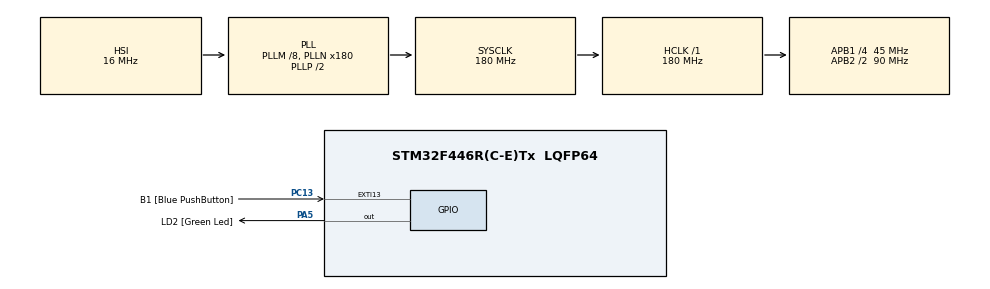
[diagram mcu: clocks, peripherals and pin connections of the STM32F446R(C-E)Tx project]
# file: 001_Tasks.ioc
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Mcu.Family=STM32F4
Mcu.Name=STM32F446R(C-E)Tx
Mcu.Package=LQFP64
NVIC.PriorityGroup=NVIC_PRIORITYGROUP_4
NVIC.TIM6_DAC_IRQn=true\:0\:0\:false\:false\:true\:false\:true\:true
NVIC.TimeBase=TIM6_DAC_IRQn
NVIC.TimeBaseIP=TIM6
PA13.GPIO_Label=TMS
PA13.Signal=SYS_JTMS-SWDIO
PA14.GPIO_Label=TCK
PA14.Signal=SYS_JTCK-SWCLK
PA2.GPIO_Label=USART_TX
PA2.Signal=USART2_TX
PA3.GPIO_Label=USART_RX
PA3.Signal=USART2_RX
PA5.GPIO_Label=LD2 [Green Led]
PA5.Signal=GPIO_Output
PB3.GPIO_Label=SWO
PB3.Signal=SYS_JTDO-SWO
PC13.GPIO_Label=B1 [Blue PushButton]
PC13.GPIO_ModeDefaultEXTI=GPIO_MODE_IT_FALLING
PC13.Signal=GPXTI13
PC14-OSC32_IN.Signal=RCC_OSC32_IN
PC15-OSC32_OUT.Signal=RCC_OSC32_OUT
PH0-OSC_IN.Signal=RCC_OSC_IN
PH1-OSC_OUT.Signal=RCC_OSC_OUT
ProjectManager.HeapSize=0x200
ProjectManager.StackSize=0x400
ProjectManager.TargetToolchain=STM32CubeIDE
RCC.AHBFreq_Value=180000000
RCC.APB1CLKDivider=RCC_HCLK_DIV4
RCC.APB1Freq_Value=45000000
RCC.APB1TimFreq_Value=90000000
RCC.APB2CLKDivider=RCC_HCLK_DIV2
RCC.APB2Freq_Value=90000000
RCC.APB2TimFreq_Value=180000000
RCC.CortexFreq_Value=180000000
RCC.FLatency-AdvancedSettings=FLASH_LATENCY_5
RCC.HCLKFreq_Value=180000000
RCC.HSE_VALUE=8000000
RCC.HSI_VALUE=16000000
RCC.LSE_VALUE=32768
RCC.PLLM=8
RCC.PLLN=180
RCC.SYSCLKFreq_VALUE=180000000
RCC.SYSCLKSource=RCC_SYSCLKSOURCE_PLLCLK
RCC.USBFreq_Value=180000000
RCC.VCOOutputFreq_Value=360000000
VP_SYS_VS_tim6.Mode=TIM6
board=NUCLEO-F446RE

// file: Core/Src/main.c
/* USER CODE BEGIN Header */
/**
  ******************************************************************************
  * @file           : main.c
  * @Author			: Abdio Tujuba
  * @brief			: Multiple task creation based on FreeRTOS
  * @IDE			; STM32CubeIDE
  * @board			: STM32F446RE NucleoBoard
  ******************************************************************************
  * @attention
  *
  * Copyright (c) 2022 STMicroelectronics.
  * All rights reserved.
  *
  * This software is licensed under terms that can be found in the LICENSE file
  * in the root directory of this software component.
  * If no LICENSE file comes with this software, it is provided AS-IS.
  *
  ******************************************************************************
  */
/* USER CODE END Header */
#include "main.h"

/* USER CODE BEGIN Includes */

#include "FreeRTOS.h"
#include "task.h"
#include <stdio.h>

/* USER CODE END Includes */

/* USER CODE BEGIN PTD */

//static UART_InitTypeDef s_USART2_Handle ;
//static UART_HandleTypeDef s_USART2_Handle;

/* USER CODE END PTD */

/* USER CODE BEGIN PV */

#define DWT_CTRL 								(*(volatile uint32_t*)0xE0001000)

/* USER CODE END PV */

void SystemClock_Config(void);
static void MX_GPIO_Init(void);
/* USER CODE BEGIN PFP */

static void task1_handler(void *parameters);
static void task2_handler(void *parameters);
/* USER CODE END PFP */

int main(void)
{
  /* USER CODE BEGIN 1 */

	TaskHandle_t task1_Handle;
	TaskHandle_t task2_Handle;

	BaseType_t status;

  /* USER CODE END 1 */

  /* MCU Configuration--------------------------------------------------------*/

  /* Reset of all peripherals, Initializes the Flash interface and the Systick. */
  HAL_Init();

  /* USER CODE BEGIN Init */
  //gpio_init();
  //uart2_rxtx_init();

  /* USER CODE END Init */

  /* Configure the system clock */
  SystemClock_Config();

  /* Initialize all configured peripherals */
  MX_GPIO_Init();
  /* USER CODE BEGIN 2 */

  DWT_CTRL|=(1U<<0);

  SEGGER_UART_init(500000);

  SEGGER_SYSVIEW_Conf();

  //SEGGER_SYSVIEW_Start();

  status =  xTaskCreate(task1_handler,"Task-1",200,"Hello World from Task 1 freeRTOS",2,&task1_Handle); // create a task , task 1

  configASSERT(status == pdPASS);

  status =  xTaskCreate(task2_handler,"Task-2",200,"Hello World from Task 2 freeRTOS",2,&task2_Handle); // Create a task, Task 2

  configASSERT(status == pdPASS);

  //start freeRTOS scheduler

  vTaskStartScheduler();

  //If the control comes here, then the launch of the scheduler has failed due to insufficient memory in the heap

  /* USER CODE END 2 */

  /* Infinite loop */
  while (1)
  {

  }
}

void SystemClock_Config(void)
{
  RCC_OscInitTypeDef RCC_OscInitStruct = {0};
  RCC_ClkInitTypeDef RCC_ClkInitStruct = {0};

  /** Configure the main internal regulator output voltage
  */
  __HAL_RCC_PWR_CLK_ENABLE();
  __HAL_PWR_VOLTAGESCALING_CONFIG(PWR_REGULATOR_VOLTAGE_SCALE1);

  /** Initializes the RCC Oscillators according to the specified parameters
  * in the RCC_OscInitTypeDef structure.
  */
  RCC_OscInitStruct.OscillatorType = RCC_OSCILLATORTYPE_HSI;
  RCC_OscInitStruct.HSIState = RCC_HSI_ON;
  RCC_OscInitStruct.HSICalibrationValue = RCC_HSICALIBRATION_DEFAULT;
  RCC_OscInitStruct.PLL.PLLState = RCC_PLL_ON;
  RCC_OscInitStruct.PLL.PLLSource = RCC_PLLSOURCE_HSI;
  RCC_OscInitStruct.PLL.PLLM = 8;
  RCC_OscInitStruct.PLL.PLLN = 180;
  RCC_OscInitStruct.PLL.PLLP = RCC_PLLP_DIV2;
  RCC_OscInitStruct.PLL.PLLQ = 2;
  RCC_OscInitStruct.PLL.PLLR = 2;
  if (HAL_RCC_OscConfig(&RCC_OscInitStruct) != HAL_OK)
  {
    Error_Handler();
  }

  /** Activate the Over-Drive mode
  */
  if (HAL_PWREx_EnableOverDrive() != HAL_OK)
  {
    Error_Handler();
  }

  /** Initializes the CPU, AHB and APB buses clocks
  */
  RCC_ClkInitStruct.ClockType = RCC_CLOCKTYPE_HCLK|RCC_CLOCKTYPE_SYSCLK
                              |RCC_CLOCKTYPE_PCLK1|RCC_CLOCKTYPE_PCLK2;
  RCC_ClkInitStruct.SYSCLKSource = RCC_SYSCLKSOURCE_PLLCLK;
  RCC_ClkInitStruct.AHBCLKDivider = RCC_SYSCLK_DIV1;
  RCC_ClkInitStruct.APB1CLKDivider = RCC_HCLK_DIV4;
  RCC_ClkInitStruct.APB2CLKDivider = RCC_HCLK_DIV2;

  if (HAL_RCC_ClockConfig(&RCC_ClkInitStruct, FLASH_LATENCY_5) != HAL_OK)
  {
    Error_Handler();
  }
}

static void MX_GPIO_Init(void)
{
  GPIO_InitTypeDef GPIO_InitStruct = {0};

  /* GPIO Ports Clock Enable */
  __HAL_RCC_GPIOC_CLK_ENABLE();
  __HAL_RCC_GPIOH_CLK_ENABLE();
  __HAL_RCC_GPIOA_CLK_ENABLE();
  __HAL_RCC_GPIOB_CLK_ENABLE();

  /*Configure GPIO pin Output Level */
  HAL_GPIO_WritePin(LD2_GPIO_Port, LD2_Pin, GPIO_PIN_RESET);

  /*Configure GPIO pin : B1_Pin */
  GPIO_InitStruct.Pin = B1_Pin;
  GPIO_InitStruct.Mode = GPIO_MODE_IT_FALLING;
  GPIO_InitStruct.Pull = GPIO_NOPULL;
  HAL_GPIO_Init(B1_GPIO_Port, &GPIO_InitStruct);

  /*Configure GPIO pins : USART_TX_Pin USART_RX_Pin */
  GPIO_InitStruct.Pin = USART_TX_Pin|USART_RX_Pin;
  GPIO_InitStruct.Mode = GPIO_MODE_AF_PP;
  GPIO_InitStruct.Pull = GPIO_NOPULL;
  GPIO_InitStruct.Speed = GPIO_SPEED_FREQ_VERY_HIGH;
  GPIO_InitStruct.Alternate = GPIO_AF7_USART2;
  HAL_GPIO_Init(GPIOA, &GPIO_InitStruct);

  /*Configure GPIO pin : LD2_Pin */
  GPIO_InitStruct.Pin = LD2_Pin;
  GPIO_InitStruct.Mode = GPIO_MODE_OUTPUT_PP;
  GPIO_InitStruct.Pull = GPIO_NOPULL;
  GPIO_InitStruct.Speed = GPIO_SPEED_FREQ_LOW;
  HAL_GPIO_Init(LD2_GPIO_Port, &GPIO_InitStruct);

}

/* USER CODE BEGIN 4 */

/*void HAL_USART2_UART_Init(void)
{
	s_UARTHandle.Instance = USART2;
	uart2.Instance = USART2;
	uart2.Init.BaudRate = 1152000;
	uart2.Init.WordLength = UART_WORDLENGTH_8B;
	uart2.Init.StopBits = UART_STOPBITS_1;
	uart2.Init.Parity = UART_PARITY_NONE;
	uart2.Init.HwFlowCtl = UART_HWCONTROL_NONE;
	uart2.Init.OverSampling = UART_OVERSAMPLING_16;
	uart2.Init.OneBitSampling = UART_ONEBIT_SAMPLING_DISABLED ;
	uart2.AdvancedInit.AdvFeatureInit = UART_ADVFEATURE_NO_INIT;
	HAL_UART_Init(&huart2);
}*/

// Task 1 handler

static void task1_handler(void *parameters)
{
   char msg[100];

	while(1){

	   //printf("%s\n",(char*)parameters);

	   snprintf(msg,100,"%s\n",(char*)parameters);

	   SEGGER_SYSVIEW_PrintfTarget(msg);
	   taskYIELD();
   }

}

// Task 2 Handler

static void task2_handler(void *parameters)
{
	char msg[100];
	 while(1){

		   //printf("%s\n",(char*)parameters);
		   snprintf(msg,100,"%s\n",(char*)parameters);
		   SEGGER_SYSVIEW_PrintfTarget(msg);
		   taskYIELD();
	   }

}

/* USER CODE END 4 */

void HAL_TIM_PeriodElapsedCallback(TIM_HandleTypeDef *htim)
{
  if (htim->Instance == TIM6) {
    HAL_IncTick();
  }
}

void Error_Handler(void)
{
  __disable_irq();
  while (1)
  {
  }
}
